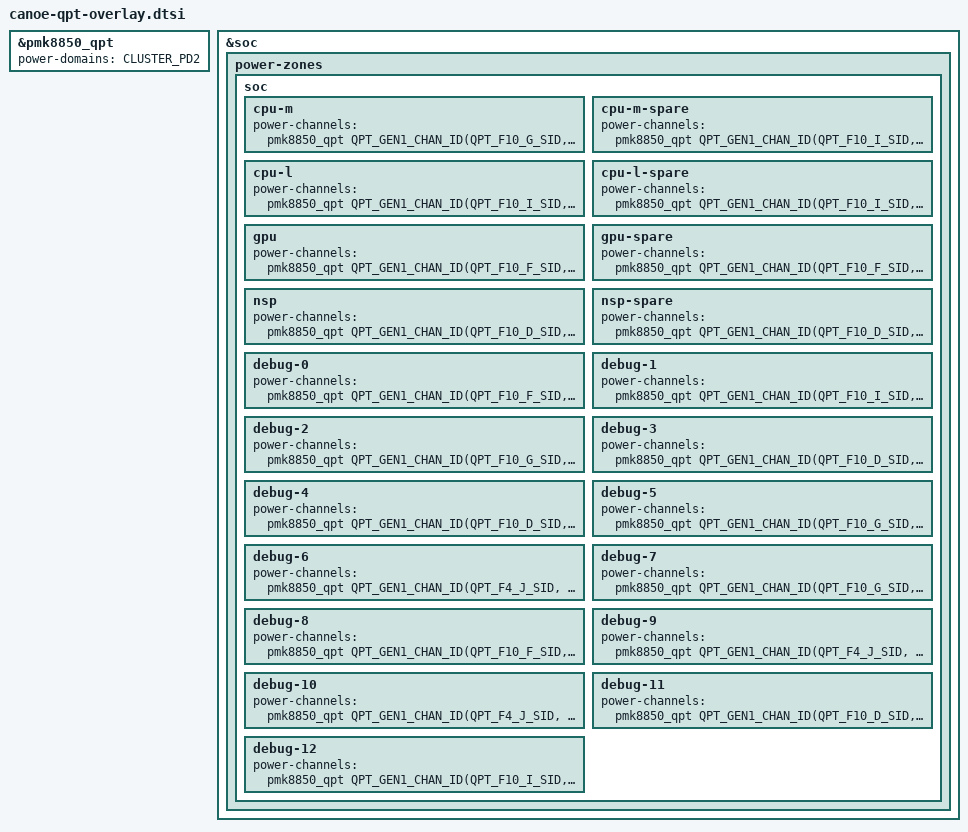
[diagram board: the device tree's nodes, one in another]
// SPDX-License-Identifier: BSD-3-Clause
/*
 * Copyright (c) Qualcomm Technologies, Inc. and/or its subsidiaries.
 */

#include <dt-bindings/soc/qcom,qpt-gen1-channels.h>

&pmk8850_qpt {
	status = "okay";
	power-domains = <&CLUSTER_PD2>;
};

&soc {
	power-zones {
		soc {
			cpu-m {
				power-channels =
					<&pmk8850_qpt QPT_GEN1_CHAN_ID(QPT_F10_G_SID, QPT_S10_REG)>;
			};

			cpu-m-spare {
				power-channels =
					<&pmk8850_qpt QPT_GEN1_CHAN_ID(QPT_F10_I_SID, QPT_S8_REG)>;
			};

			cpu-l {
				power-channels =
					<&pmk8850_qpt QPT_GEN1_CHAN_ID(QPT_F10_I_SID, QPT_S2_REG)>;
			};

			cpu-l-spare {
				power-channels =
					 <&pmk8850_qpt QPT_GEN1_CHAN_ID(QPT_F10_I_SID, QPT_S9_REG)>;
			};

			gpu {
				power-channels =
					<&pmk8850_qpt QPT_GEN1_CHAN_ID(QPT_F10_F_SID, QPT_S1_REG)>;
			};

			gpu-spare {
				power-channels =
					<&pmk8850_qpt QPT_GEN1_CHAN_ID(QPT_F10_F_SID, QPT_S10_REG)>;
			};

			nsp {
				power-channels =
					<&pmk8850_qpt QPT_GEN1_CHAN_ID(QPT_F10_D_SID, QPT_S2_REG)>;
			};

			nsp-spare {
				power-channels =
					<&pmk8850_qpt QPT_GEN1_CHAN_ID(QPT_F10_D_SID, QPT_S4_REG)>;
			};

			debug-0 {
				power-channels =
					<&pmk8850_qpt QPT_GEN1_CHAN_ID(QPT_F10_F_SID, QPT_S9_REG)>;
			};

			debug-1 {
				power-channels =
					<&pmk8850_qpt QPT_GEN1_CHAN_ID(QPT_F10_I_SID, QPT_S10_REG)>;
			};

			debug-2 {
				power-channels =
					<&pmk8850_qpt QPT_GEN1_CHAN_ID(QPT_F10_G_SID, QPT_S5_REG)>;
			};

			debug-3 {
				power-channels =
					<&pmk8850_qpt QPT_GEN1_CHAN_ID(QPT_F10_D_SID, QPT_S1_REG)>;
			};

			debug-4 {
				power-channels =
					<&pmk8850_qpt QPT_GEN1_CHAN_ID(QPT_F10_D_SID, QPT_S7_REG)>;
			};

			debug-5 {
				power-channels =
					<&pmk8850_qpt QPT_GEN1_CHAN_ID(QPT_F10_G_SID, QPT_S8_REG)>;
			};

			debug-6 {
				power-channels =
					<&pmk8850_qpt QPT_GEN1_CHAN_ID(QPT_F4_J_SID, QPT_S4_REG)>;
			};

			debug-7 {
				power-channels =
					<&pmk8850_qpt QPT_GEN1_CHAN_ID(QPT_F10_G_SID, QPT_S7_REG)>;
			};

			debug-8 {
				power-channels =
					<&pmk8850_qpt QPT_GEN1_CHAN_ID(QPT_F10_F_SID, QPT_S7_REG)>;
			};

			debug-9 {
				power-channels =
					<&pmk8850_qpt QPT_GEN1_CHAN_ID(QPT_F4_J_SID, QPT_S2_REG)>;
			};

			debug-10 {
				power-channels =
					<&pmk8850_qpt QPT_GEN1_CHAN_ID(QPT_F4_J_SID, QPT_S3_REG)>;
			};

			debug-11 {
				power-channels =
					<&pmk8850_qpt QPT_GEN1_CHAN_ID(QPT_F10_D_SID, QPT_S10_REG)>;
			};

			debug-12 {
				power-channels =
					<&pmk8850_qpt QPT_GEN1_CHAN_ID(QPT_F10_I_SID, QPT_S7_REG)>;
			};
		};
	};
};
